# R7FA0L107 register map
Vendor: Renesas Electronics Corporation; Series: RA0; File version: 1.10.01
CPU: CM23 r1p0, little endian, no MPU, no FPU, VTOR, 2 interrupt priority bits, 64 interrupts
Registers are 16-bit, read-write, reset 0x0 unless marked. A register's access mark holds for its fields unless they carry their own. Offsets are from the block's base; [hi:lo] are bit positions; {n}, {i} and the like mark numbered series; <NAME> marks a mode.

## SYSC — System Control
Base 0x4001E000
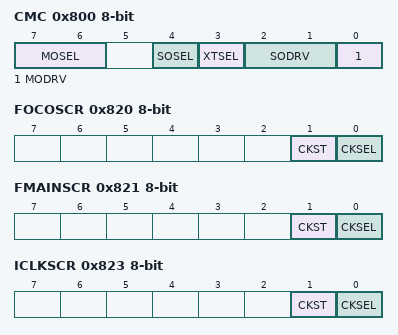
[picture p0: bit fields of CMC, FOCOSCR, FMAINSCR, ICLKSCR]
0x800 CMC 8-bit — Clock Operation Mode Control Register
  [7:6] MOSEL — Main Clock Oscillator Switching
    1=Resonator; 3=External clock input mode; other=Others (Port mode)
  [4] SOSEL — Sub-clock Oscillator Switching
    0=Port mode; 1=Resonator
  [3] XTSEL — Selecting Clock Oscillator
    0=Select MOSEL Contents; 1=Select SOSEL Contents
  [2:1] SODRV — Sub-clock Oscillator Drive Capability Switching
    0=Low Power Mode 1; 1=Normal Mode; 2=Low Power Mode 2; 3=Low Power Mode 3
  [0] MODRV — Main Clock Oscillator Drive Capability Switching
    0=1 MHz to 10 MHz; 1=10 MHz to 20 MHz
0x803 SOMRG 8-bit — Sub-clock Oscillator Margin Check Register
  [1:0] SOSCMRG — Sub-clock Oscillator Margin Check Switching
    0=Normal Current; 1=Lower Margin check; 2=Upper Margin check; 3=Setting prohibited
0x804 MIOTRM 8-bit reset 0x90 — Middle-speed On-chip Oscillator Trimming Register
  [7:0] MIOTRM — MOCO User Trimming
0x805 LIOTRM 8-bit reset 0x80 — Low-speed On-chip Oscillator Trimming Register
  [7:0] LIOTRM — LOCO User Trimming
0x808 HOCOCR 8-bit — High-speed On-chip Oscillator Control Register
  [0] HCSTP — HOCO Stop
    0=Operate the HOCO clock; 1=Stop the HOCO clock
0x809 MOCOCR 8-bit reset 0x1 — Middle-speed On-chip Oscillator Control Register
  [0] MCSTP — MOCO Stop
    0=MOCO clock is operating; 1=MOCO clock is stopped
0x80A LOCOCR 8-bit reset 0x1 — Low-speed On-chip Oscillator Control Register
  [0] LCSTP — LOCO Stop
    0=Operate the LOCO clock; 1=Stop the LOCO clock
0x80B MOSCCR 8-bit reset 0x1 — Main Clock Oscillator Control Register
  [0] MOSTP — Main Clock Oscillator Stop
    0=Operate the main clock oscillator; 1=Stop the main clock oscillator
0x80C SOSCCR 8-bit reset 0x1 — Sub-clock Oscillator Control Register
  [0] SOSTP — Sub-clock Oscillator Stop
    0=Operate the sub-clock oscillator; 1=Stop the sub-clock oscillator
0x810 OSTC 8-bit ro — Oscillation Stabilization Time Counter Status Register
  [7:0] MOST — Selection of the Oscillation Stabilization Time
    0=Less than 28/fMOSC; 128=28/fMOSC min; 192=29/fMOSC min; 224=210/fMOSC min; 240=211/fMOSC min; 248=213/fMOSC min; 252=215/fMOSC min; 254=217/fMOSC min; 255=218/fMOSC min
0x811 OSTS 8-bit reset 0x7 — Oscillation Stabilization Time Select Register
  [2:0] OSTSB — Selection of the Oscillation Stabilization Time
    0=28/fMOSC; 1=29/fMOSC; 2=210/fMOSC; 3=211/fMOSC; 4=213/fMOSC; 5=215/fMOSC; 6=217/fMOSC; 7=218/fMOSC
0x812 OSCSF 8-bit ro reset 0x1 — Oscillation Stabilization Flag Register
  [0] HOCOSF — HOCO Clock Oscillation Stabilization Flag
    0=The HOCO clock is being started at high speed and waiting for the precision of its oscillation to become stable is in progress; 1=The HOCO clock is operating with high precision
0x818 HOCODIV 8-bit reset 0x3 — High-speed On-chip Oscillator Frequency Select Register
  [2:0] DIV — High-speed On-chip Oscillator Clock Division Ratio
    0=× 1/1; 1=× 1/2; 2=× 1/4; 3=× 1/8; 4=× 1/16; 5=× 1/32; other=Others (Setting prohibited)
0x819 MOCODIV 8-bit — Middle-speed On-chip Oscillator Frequency Select Register
  [1:0] DIV — Selection of the Middle-speed On-chip Oscillator Clock Frequency
    0=× 1/1; 1=× 1/2; 2=× 1/4; other=Others (Setting prohibited)
0x81A MOSCDIV 8-bit — MOSC Clock Division Register
  [2:0] DIV — Selection Division Ratio for the MOSC Clock
    0=× 1/1; 1=× 1/2; 2=× 1/4; 3=× 1/8; 4=× 1/16; other=Others (Setting prohibited)
0x820 FOCOSCR 8-bit — FOCO Clock Source Control Register
  [1] CKST ro — FOCO Clock Source Status
    0=HOCO; 1=MOCO
  [0] CKSEL — FOCO Clock Source Select
    0=HOCO; 1=MOCO
0x821 FMAINSCR 8-bit — FMAIN Clock Source Control Register
  [1] CKST ro — FMAIN Clock Source Status
    0=FOCO; 1=MOSC
  [0] CKSEL — FMAIN Clock Source Select
    0=FOCO; 1=MOSC
0x822 FSUBSCR 8-bit — FSUB Clock Source Control Register
  [0] CKSEL — FSUB Clock Source Select
    0=SOSC; 1=LOCO
0x823 ICLKSCR 8-bit — ICLK Clock Source Control Register
  [1] CKST ro — ICLK Clock Source Status
    0=FMAIN; 1=FSUB
  [0] CKSEL — ICLK Clock Source Select
    0=FMAIN; 1=FSUB
0x824 OSMC 8-bit — Subsystem Clock Supply Mode Control Register
  [4] WUTMMCK0 — Selection of the operating clock source for the realtime clock, 32-bit interval timer, serial interface UARTA
    0=SOSC; 1=LOCO
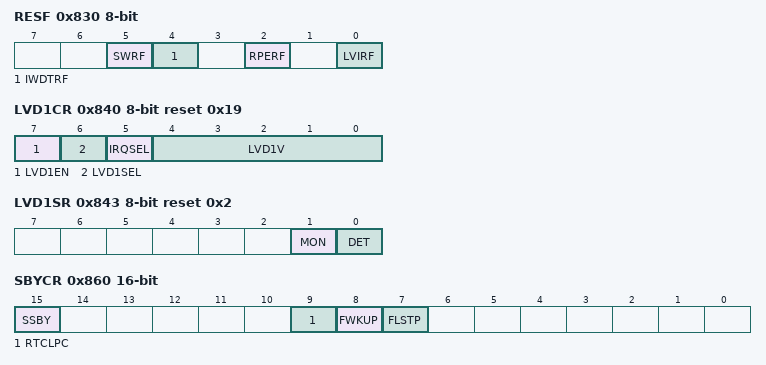
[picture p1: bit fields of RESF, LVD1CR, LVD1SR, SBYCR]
0x830 RESF 8-bit ro (reset mask 0xCA) — Reset Status Flag Register
  [all] fields
    0=Internal reset request is not generated, or the RESF register is cleared; 1=Internal reset request is generated
  [5] SWRF — Internal Reset Request by Software Reset
  [4] IWDTRF — Internal Reset Request by Independent Watchdog Timer (IWDT)
  [2] RPERF — Internal Reset Request by RAM Parity Error
  [0] LVIRF — Internal Reset Request by Voltage Detector (LVD0 or LVD1)
0x831 PORSR 8-bit — Power-On Reset Status Register
  [0] PORF — Checking Occurrence of Power-on Reset
    0=A value 1 has not been written, or a power-on reset has occurred; 1=No power-on reset has occurred
0x840 LVD1CR 8-bit reset 0x19 — Voltage Monitor 1 Circuit Control Register
  [7] LVD1EN — Enabling Operation of LVD1
    0=Operation stopped; 1=Operation enabled
  [6] LVD1SEL — Operation mode of LVD1
    0=Interrupt mode; 1=Reset mode
  [5] IRQSEL — Voltage Monitor 1 Interrupt Type Select
    0=Non-maskable interrupt; 1=Maskable interrupt
  [4:0] LVD1V — Voltage Detection 1 Level Select
    {v}=Vdet1_{v-14} (v=14..23); 24=Vdet1_A; 25=Vdet1_B; 26=Vdet1_C; 27=Vdet1_D; 28=Vdet1_E; 29=Vdet1_F; 30=Vdet1_10; 31=Vdet1_11; other=Others (Setting prohibited)
0x841 LVD1MKR 8-bit — Voltage Monitor 1 Circuit Mask Register
  [0] MK — Specification of Whether to Enable or Disable Rewriting the LVD1CR Register
    0=Rewriting of the LVD1CR register is disabled; 1=Rewriting of the LVD1CR register is enabled (reset and interrupt generation by LVD1 are masked)
0x843 LVD1SR 8-bit reset 0x2 — Voltage Monitor 1 Circuit Status Register
  [1] MON ro — Voltage Monitor 1 Signal Monitor Flag
    0=VCC < Vdet1; 1=VCC ≥ Vdet1 or MON is disabled
  [0] DET — Voltage Monitor 1 Voltage Variation Detection Flag
    0=Not detected; 1=Vdet1 crossing is detected
0x860 SBYCR — Standby Control Register
  [15] SSBY — Software Standby Mode Select
    0=Sleep mode; 1=Software Standby mode
  [9] RTCLPC — SOSC Setting in Software Standby Mode or in Snooze Mode
    0=Enables supply of SOSC clock to peripheral functions; 1=Stops supply SOSC clock to peripheral functions other than the Realtime clock
  [8] FWKUP — Setting for Starting the High-speed On-chip Oscillator at the times of release from Software Standby Mode and of Transitions to Snooze Mode
    0=Starting of the high-speed on-chip oscillator is at normal speed; 1=Starting of the high-speed on-chip oscillator is at high speed
  [7] FLSTP — Flash Mode in Sleep Mode or in Snooze Mode
    0=Flash active; 1=Flash stop
0x862 PSMCR 8-bit — Power Save Memory Control Register
  [1:0] RAMSD — Operating Mode of the RAM
    0=Normal mode (continues to operate); 1=Setting prohibited; 2=Standby mode; 3=Shutdown mode
0x863 SYOCDCR 8-bit — System Control OCD Control Register
  [7] DBGEN — Debugger Enable bit
    0=On-chip debugger is disabled; 1=On-chip debugger is enabled
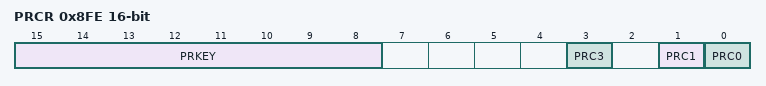
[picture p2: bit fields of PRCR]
0x8FE PRCR — Protect Register
  [15:8] PRKEY wo — PRC Key Code
  [3] PRC3 — Enable writing to the registers related to the LVD
    0=Disable writes; 1=Enable writes
  [1] PRC1 — Enable writing to the registers related to the low power modes
    0=Disable writes; 1=Enable writes
  [0] PRC0 — Enable writing to the registers related to the clock generation circuit
    0=Disable writes; 1=Enable writes
0xC02 MSTPCRA reset 0xFFBF — Module Stop Control Register A
  [6] MSTPA22 — DTC Module Stop
    0=Cancel the module-stop state; 1=Enter the module-stop state
